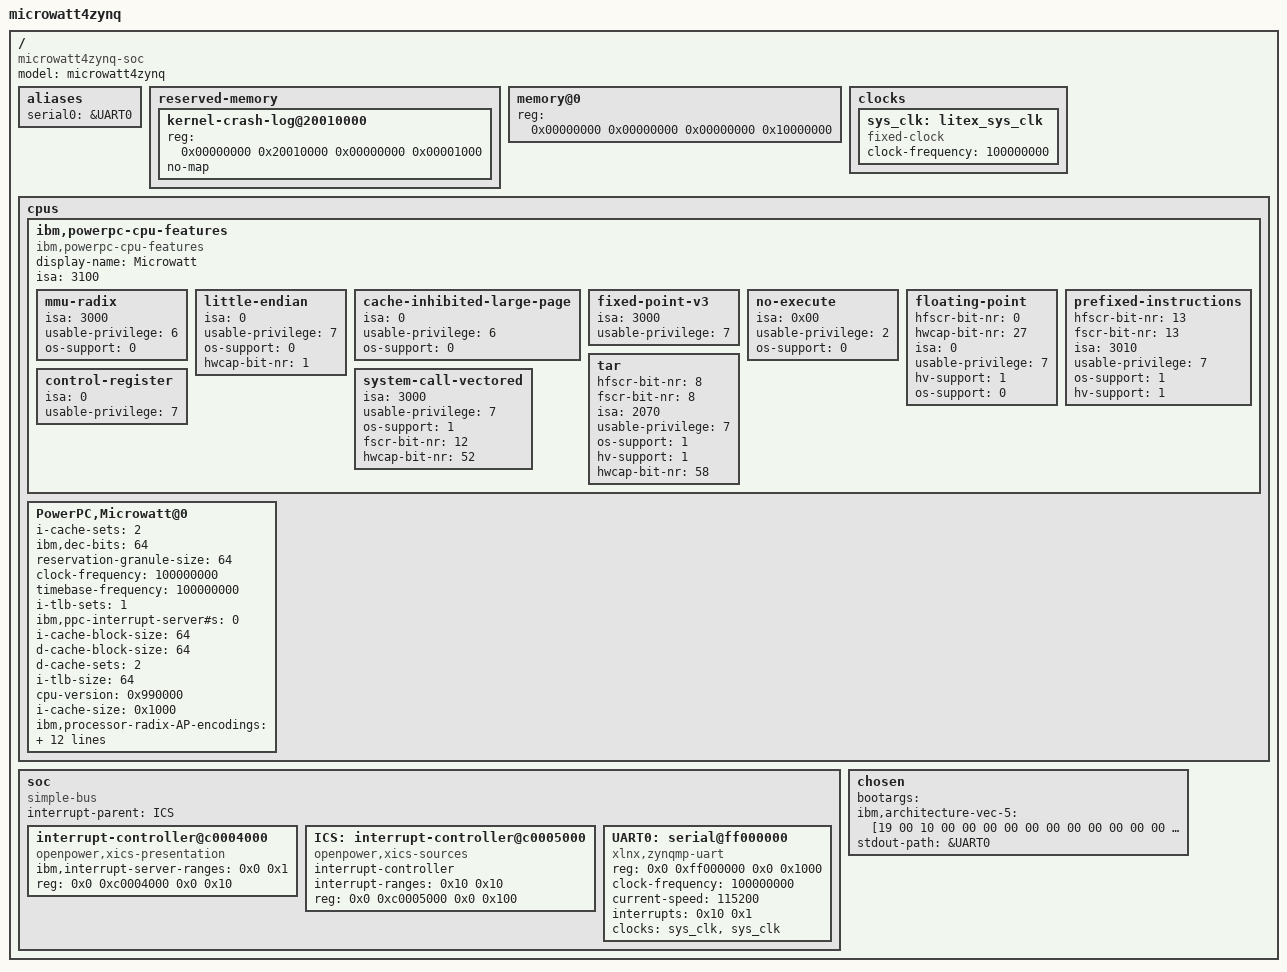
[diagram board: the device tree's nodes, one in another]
/dts-v1/;
#include <dt-bindings/gpio/gpio.h>

/ {
	#size-cells = <0x02>;
	#address-cells = <0x02>;
	model = "microwatt4zynq";
	compatible = "microwatt4zynq-soc";

	aliases {
		serial0 = &UART0;
	};

	reserved-memory {
		#size-cells = <0x02>;
		#address-cells = <0x02>;
		ranges;

		kernel-crash-log@20010000 {
			reg = <0x00000000 0x20010000  0x00000000 0x00001000>; /* 4 KiB at 0x20010000 */
			no-map;
		};
	};

	memory@0 {
		device_type = "memory";
		reg = <0x00000000 0x00000000 0x00000000 0x10000000>;
	};

	clocks {
		sys_clk: litex_sys_clk {
			#clock-cells = <0>;
			compatible = "fixed-clock";
			clock-frequency = <100000000>;
		};
	};

	cpus {
		#size-cells = <0x00>;
		#address-cells = <0x01>;

		ibm,powerpc-cpu-features {
			display-name = "Microwatt";
			isa = <3100>;
			device_type = "cpu-features";
			compatible = "ibm,powerpc-cpu-features";

			mmu-radix {
				isa = <3000>;
				usable-privilege = <6>;
				os-support = <0>;
			};

			little-endian {
				isa = <0>;
				usable-privilege = <7>;
				os-support = <0>;
				hwcap-bit-nr = <1>;
			};

			cache-inhibited-large-page {
				isa = <0>;
				usable-privilege = <6>;
				os-support = <0>;
			};

			fixed-point-v3 {
				isa = <3000>;
				usable-privilege = <7>;
			};

			no-execute {
				isa = <0x00>;
				usable-privilege = <2>;
				os-support = <0>;
			};

			floating-point {
				hfscr-bit-nr = <0>;
				hwcap-bit-nr = <27>;
				isa = <0>;
				usable-privilege = <7>;
				hv-support = <1>;
				os-support = <0>;
			};

			prefixed-instructions {
				hfscr-bit-nr = <13>;
				fscr-bit-nr = <13>;
				isa = <3010>;
				usable-privilege = <7>;
				os-support = <1>;
				hv-support = <1>;
			};

			tar {
				hfscr-bit-nr = <8>;
				fscr-bit-nr = <8>;
				isa = <2070>;
				usable-privilege = <7>;
				os-support = <1>;
				hv-support = <1>;
				hwcap-bit-nr = <58>;
			};

			control-register {
				isa = <0>;
				usable-privilege = <7>;
			};

			system-call-vectored {
				isa = <3000>;
				usable-privilege = <7>;
				os-support = <1>;
				fscr-bit-nr = <12>;
				hwcap-bit-nr = <52>;
			};
		};

		PowerPC,Microwatt@0 {
			i-cache-sets = <2>;
			ibm,dec-bits = <64>;
			reservation-granule-size = <64>;
			clock-frequency = <100000000>;
			timebase-frequency = <100000000>;
			i-tlb-sets = <1>;
			ibm,ppc-interrupt-server#s = <0>;
			i-cache-block-size = <64>;
			d-cache-block-size = <64>;
			d-cache-sets = <2>;
			i-tlb-size = <64>;
			cpu-version = <0x990000>;
			status = "okay";
			i-cache-size = <0x1000>;
			ibm,processor-radix-AP-encodings = <0x0c 0xa0000010 0x20000015 0x4000001e>;
			tlb-size = <0>;
			tlb-sets = <0>;
			device_type = "cpu";
			d-tlb-size = <128>;
			d-tlb-sets = <2>;
			reg = <0>;
			general-purpose;
			64-bit;
			d-cache-size = <0x1000>;
			ibm,chip-id = <0>;
			ibm,mmu-lpid-bits = <12>;
			ibm,mmu-pid-bits = <20>;
		};
	};

	soc {
		compatible = "simple-bus";
		#address-cells = <0x02>;
		#size-cells = <0x02>;
		interrupt-parent = <&ICS>;
		ranges;

		interrupt-controller@c0004000 {
			compatible = "openpower,xics-presentation", "ibm,ppc-xicp";
			ibm,interrupt-server-ranges = <0x0 0x1>;
			reg = <0x0 0xc0004000 0x0 0x10>;
		};

		ICS: interrupt-controller@c0005000 {
			compatible = "openpower,xics-sources";
			interrupt-controller;
			interrupt-ranges = <0x10 0x10>;
			reg = <0x0 0xc0005000 0x0 0x100>;
			#address-cells = <0>;
			#size-cells = <0>;
			#interrupt-cells = <2>;
		};

		UART0: serial@ff000000 {
			device_type = "serial";
			compatible = "xlnx,zynqmp-uart";
			reg = <0x0 0xff000000 0x0 0x1000>;
			clock-frequency = <100000000>;
			current-speed = <115200>;
			interrupts = <0x10 0x1>;
			clock-names = "uart_clk", "pclk";
			clocks = <&sys_clk>, <&sys_clk>;
		};
	};

	chosen {
		bootargs = "";
		ibm,architecture-vec-5 = [19 00 10 00 00 00 00 00 00 00 00 00 00 00 00 00
					  00 00 00 00 00 00 00 00 40 00 40];
		stdout-path = &UART0;
	};
};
